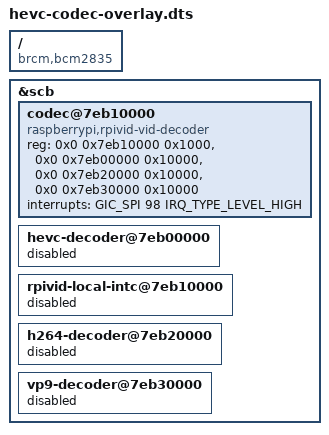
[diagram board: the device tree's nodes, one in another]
// SPDX-License-Identifier: GPL-2.0-only
// Definitions for Raspberry Pi video decode engine
/dts-v1/;
/plugin/;


#include <dt-bindings/interrupt-controller/arm-gic.h>

/{
	compatible = "brcm,bcm2835";

	fragment@0 {
		target = <&scb>;
		__overlay__ {
			codec@7eb10000 {
				compatible = "raspberrypi,rpivid-vid-decoder";
				reg = <0x0 0x7eb10000 0x1000>,	/* INTC */
				      <0x0 0x7eb00000 0x10000>, /* HEVC */
				      <0x0 0x7eb20000 0x10000>, /* H264 */
				      <0x0 0x7eb30000 0x10000>; /* VP9 */

				interrupts = <GIC_SPI 98 IRQ_TYPE_LEVEL_HIGH>;
			};
		};
	};

	fragment@1 {
		target = <&scb>;
		__overlay__ {
			hevc-decoder@7eb00000 {
				status = "disabled";
			};
			rpivid-local-intc@7eb10000 {
				status = "disabled";
			};
			h264-decoder@7eb20000 {
				status = "disabled";
			};
			vp9-decoder@7eb30000 {
				status = "disabled";
			};
		};
	};
};
